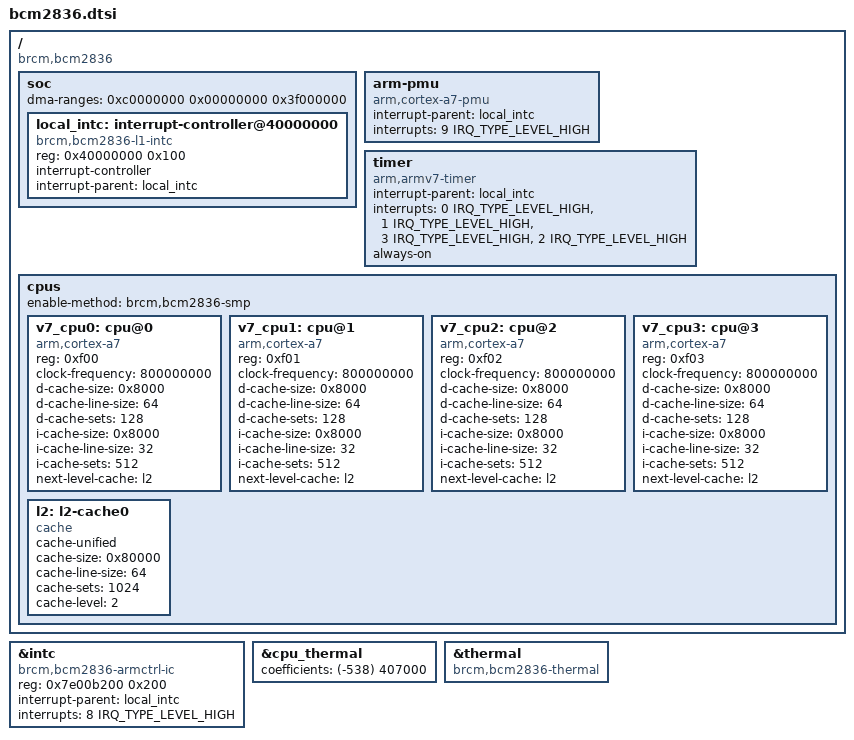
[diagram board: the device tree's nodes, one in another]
#include "bcm283x.dtsi"
#include "bcm2835-common.dtsi"
/ {
	compatible = "brcm,bcm2836";
	soc {
		ranges = <0x7e000000 0x3f000000 0x1000000>,
			 <0x40000000 0x40000000 0x00001000>;
		dma-ranges = <0xc0000000 0x00000000 0x3f000000>;
		local_intc: interrupt-controller@40000000 {
			compatible = "brcm,bcm2836-l1-intc";
			reg = <0x40000000 0x100>;
			interrupt-controller;
			#interrupt-cells = <2>;
			interrupt-parent = <&local_intc>;
		};
	};
	arm-pmu {
		compatible = "arm,cortex-a7-pmu";
		interrupt-parent = <&local_intc>;
		interrupts = <9 IRQ_TYPE_LEVEL_HIGH>;
	};
	timer {
		compatible = "arm,armv7-timer";
		interrupt-parent = <&local_intc>;
		interrupts = <0 IRQ_TYPE_LEVEL_HIGH>,  
			     <1 IRQ_TYPE_LEVEL_HIGH>,  
			     <3 IRQ_TYPE_LEVEL_HIGH>,  
			     <2 IRQ_TYPE_LEVEL_HIGH>;  
		always-on;
	};
	cpus: cpus {
		#address-cells = <1>;
		#size-cells = <0>;
		enable-method = "brcm,bcm2836-smp";
		v7_cpu0: cpu@0 {
			device_type = "cpu";
			compatible = "arm,cortex-a7";
			reg = <0xf00>;
			clock-frequency = <800000000>;
			d-cache-size = <0x8000>;
			d-cache-line-size = <64>;
			d-cache-sets = <128>;  
			i-cache-size = <0x8000>;
			i-cache-line-size = <32>;
			i-cache-sets = <512>;  
			next-level-cache = <&l2>;
		};
		v7_cpu1: cpu@1 {
			device_type = "cpu";
			compatible = "arm,cortex-a7";
			reg = <0xf01>;
			clock-frequency = <800000000>;
			d-cache-size = <0x8000>;
			d-cache-line-size = <64>;
			d-cache-sets = <128>;  
			i-cache-size = <0x8000>;
			i-cache-line-size = <32>;
			i-cache-sets = <512>;  
			next-level-cache = <&l2>;
		};
		v7_cpu2: cpu@2 {
			device_type = "cpu";
			compatible = "arm,cortex-a7";
			reg = <0xf02>;
			clock-frequency = <800000000>;
			d-cache-size = <0x8000>;
			d-cache-line-size = <64>;
			d-cache-sets = <128>;  
			i-cache-size = <0x8000>;
			i-cache-line-size = <32>;
			i-cache-sets = <512>;  
			next-level-cache = <&l2>;
		};
		v7_cpu3: cpu@3 {
			device_type = "cpu";
			compatible = "arm,cortex-a7";
			reg = <0xf03>;
			clock-frequency = <800000000>;
			d-cache-size = <0x8000>;
			d-cache-line-size = <64>;
			d-cache-sets = <128>;  
			i-cache-size = <0x8000>;
			i-cache-line-size = <32>;
			i-cache-sets = <512>;  
			next-level-cache = <&l2>;
		};
		l2: l2-cache0 {
			compatible = "cache";
			cache-unified;
			cache-size = <0x80000>;
			cache-line-size = <64>;
			cache-sets = <1024>;  
			cache-level = <2>;
		};
	};
};
&intc {
	compatible = "brcm,bcm2836-armctrl-ic";
	reg = <0x7e00b200 0x200>;
	interrupt-parent = <&local_intc>;
	interrupts = <8 IRQ_TYPE_LEVEL_HIGH>;
};
&cpu_thermal {
	coefficients = <(-538)	407000>;
};
&thermal {
	compatible = "brcm,bcm2836-thermal";
	status = "okay";
};
